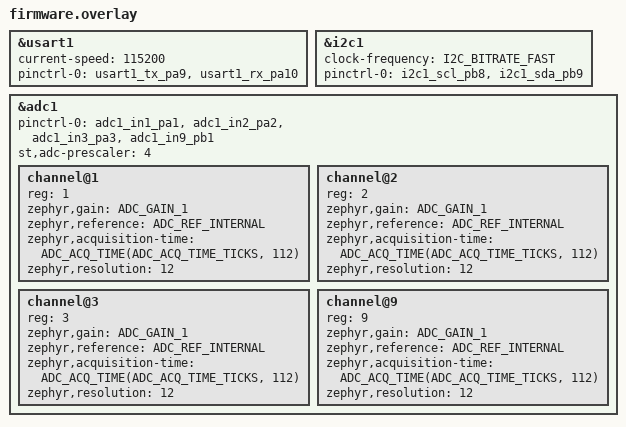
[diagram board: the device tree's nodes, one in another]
&usart1 {
    current-speed = <115200>;
    pinctrl-0 = <&usart1_tx_pa9 &usart1_rx_pa10>;
    pinctrl-names = "default";
};

&i2c1 {
    clock-frequency = <I2C_BITRATE_FAST>;
    pinctrl-0 = <&i2c1_scl_pb8 &i2c1_sda_pb9>;
    pinctrl-names = "default";
};

&adc1 {
    pinctrl-0 = <&adc1_in1_pa1
                 &adc1_in2_pa2
                 &adc1_in3_pa3
                 &adc1_in9_pb1>;
    pinctrl-names = "default";
    st,adc-prescaler = <4>;
    status = "okay";

    #address-cells = <1>;
    #size-cells = <0>;

    channel@1 {
        reg = <1>;
        zephyr,gain = "ADC_GAIN_1";
        zephyr,reference = "ADC_REF_INTERNAL";
        zephyr,acquisition-time = <ADC_ACQ_TIME(ADC_ACQ_TIME_TICKS, 112)>;
        zephyr,resolution = <12>;
    };

    channel@2 {
        reg = <2>;
        zephyr,gain = "ADC_GAIN_1";
        zephyr,reference = "ADC_REF_INTERNAL";
        zephyr,acquisition-time = <ADC_ACQ_TIME(ADC_ACQ_TIME_TICKS, 112)>;
        zephyr,resolution = <12>;
    };

    channel@3 {
        reg = <3>;
        zephyr,gain = "ADC_GAIN_1";
        zephyr,reference = "ADC_REF_INTERNAL";
        zephyr,acquisition-time = <ADC_ACQ_TIME(ADC_ACQ_TIME_TICKS, 112)>;
        zephyr,resolution = <12>;
    };

    channel@9 {
        reg = <9>;
        zephyr,gain = "ADC_GAIN_1";
        zephyr,reference = "ADC_REF_INTERNAL";
        zephyr,acquisition-time = <ADC_ACQ_TIME(ADC_ACQ_TIME_TICKS, 112)>;
        zephyr,resolution = <12>;
    };
};
